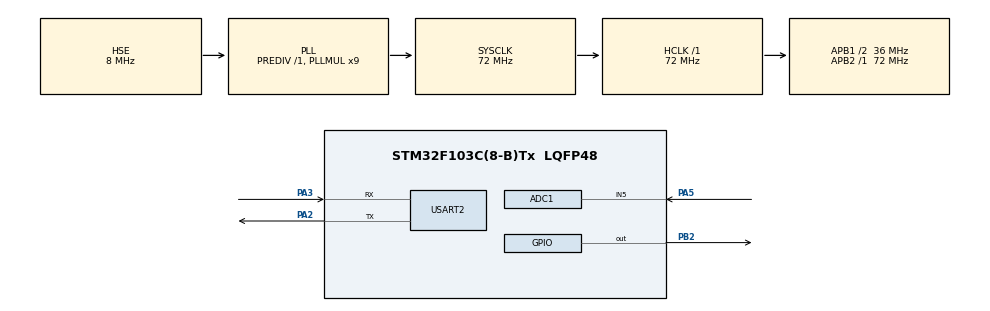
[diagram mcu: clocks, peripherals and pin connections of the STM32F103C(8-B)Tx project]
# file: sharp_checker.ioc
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ADC1.Channel-0\#ChannelRegularConversion=ADC_CHANNEL_5
ADC1.NbrOfConversionFlag=1
ADC1.Rank-0\#ChannelRegularConversion=1
ADC1.SamplingTime-0\#ChannelRegularConversion=ADC_SAMPLETIME_13CYCLES_5
ADC1.master=1
Mcu.Family=STM32F1
Mcu.Name=STM32F103C(8-B)Tx
Mcu.Package=LQFP48
NVIC.PriorityGroup=NVIC_PRIORITYGROUP_4
PA13.Mode=Serial_Wire
PA13.Signal=SYS_JTMS-SWDIO
PA14.Mode=Serial_Wire
PA14.Signal=SYS_JTCK-SWCLK
PA2.Mode=Asynchronous
PA2.Signal=USART2_TX
PA3.Mode=Asynchronous
PA3.Signal=USART2_RX
PA5.Signal=SharedAnalog_PA5
PB2.Signal=GPIO_Output
PD0-OSC_IN.Mode=HSE-External-Oscillator
PD0-OSC_IN.Signal=RCC_OSC_IN
PD1-OSC_OUT.Mode=HSE-External-Oscillator
PD1-OSC_OUT.Signal=RCC_OSC_OUT
ProjectManager.HeapSize=0x200
ProjectManager.StackSize=0x400
ProjectManager.TargetToolchain=STM32CubeIDE
RCC.AHBFreq_Value=72000000
RCC.APB1CLKDivider=RCC_HCLK_DIV2
RCC.APB1Freq_Value=36000000
RCC.APB1TimFreq_Value=72000000
RCC.APB2Freq_Value=72000000
RCC.APB2TimFreq_Value=72000000
RCC.EnbaleCSS=true
RCC.HCLKFreq_Value=72000000
RCC.PLLMUL=RCC_PLL_MUL9
RCC.PLLSourceVirtual=RCC_PLLSOURCE_HSE
RCC.SYSCLKFreq_VALUE=72000000
RCC.SYSCLKSource=RCC_SYSCLKSOURCE_PLLCLK
RCC.USBFreq_Value=72000000
SH.SharedAnalog_PA5.0=GPIO_Analog
SH.SharedAnalog_PA5.1=ADC1_IN5,IN5
USART2.VirtualMode=VM_ASYNC
board=custom

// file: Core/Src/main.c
/* USER CODE BEGIN Header */
/**
  ******************************************************************************
  * @file           : main.c
  * @brief          : Main program body
  ******************************************************************************
  * @attention
  *
  * Copyright (c) 2024 STMicroelectronics.
  * All rights reserved.
  *
  * This software is licensed under terms that can be found in the LICENSE file
  * in the root directory of this software component.
  * If no LICENSE file comes with this software, it is provided AS-IS.
  *
  ******************************************************************************
  */
/* USER CODE END Header */
#include "main.h"

#define MIN_DELAY 50  // Minimum delay in milliseconds
#define MAX_DELAY 1000 // Maximum delay in milliseconds

ADC_HandleTypeDef hadc1;
UART_HandleTypeDef huart2;

void SystemClock_Config(void);
static void MX_GPIO_Init(void);
static void MX_ADC1_Init(void);
static void MX_USART2_UART_Init(void);
uint32_t Read_Sharp_Sensor(void);

int main(void)
{

  /* MCU Configuration--------------------------------------------------------*/

  /* Reset of all peripherals, Initializes the Flash interface and the Systick. */
  HAL_Init();

  /* Configure the system clock */
  SystemClock_Config();

  /* Initialize all configured peripherals */
  MX_GPIO_Init();
  MX_ADC1_Init();
  MX_USART2_UART_Init();

  /* Infinite loop */
  /* USER CODE BEGIN WHILE */
  while (1)
  {
    uint32_t sensor_value = Read_Sharp_Sensor();
    uint32_t delay_time = MAX_DELAY - (sensor_value / 2); // Increase sensitivity

    // Ensure delay_time is within bounds
    if (delay_time < MIN_DELAY) {
      delay_time = MIN_DELAY;
    }

    HAL_GPIO_TogglePin(GPIOB, GPIO_PIN_2);
    HAL_Delay(delay_time);

    /* USER CODE END WHILE */

  }
}

/**
  * @ System Clock Configuration
  * @retval None
  */
void SystemClock_Config(void)
{
  RCC_OscInitTypeDef RCC_OscInitStruct = {0};
  RCC_ClkInitTypeDef RCC_ClkInitStruct = {0};
  RCC_PeriphCLKInitTypeDef PeriphClkInit = {0};

  /** Initializes the RCC Oscillators according to the specified parameters
  * in the RCC_OscInitTypeDef structure.
  */
  RCC_OscInitStruct.OscillatorType = RCC_OSCILLATORTYPE_HSE;
  RCC_OscInitStruct.HSEState = RCC_HSE_ON;
  RCC_OscInitStruct.HSEPredivValue = RCC_HSE_PREDIV_DIV1;
  RCC_OscInitStruct.HSIState = RCC_HSI_ON;
  RCC_OscInitStruct.PLL.PLLState = RCC_PLL_ON;
  RCC_OscInitStruct.PLL.PLLSource = RCC_PLLSOURCE_HSE;
  RCC_OscInitStruct.PLL.PLLMUL = RCC_PLL_MUL9;
  if (HAL_RCC_OscConfig(&RCC_OscInitStruct) != HAL_OK)
  {
    Error_Handler();
  }

  /** Initializes the CPU, AHB and APB buses clocks
  */
  RCC_ClkInitStruct.ClockType = RCC_CLOCKTYPE_HCLK|RCC_CLOCKTYPE_SYSCLK
                              |RCC_CLOCKTYPE_PCLK1|RCC_CLOCKTYPE_PCLK2;
  RCC_ClkInitStruct.SYSCLKSource = RCC_SYSCLKSOURCE_PLLCLK;
  RCC_ClkInitStruct.AHBCLKDivider = RCC_SYSCLK_DIV1;
  RCC_ClkInitStruct.APB1CLKDivider = RCC_HCLK_DIV2;
  RCC_ClkInitStruct.APB2CLKDivider = RCC_HCLK_DIV1;

  if (HAL_RCC_ClockConfig(&RCC_ClkInitStruct, FLASH_LATENCY_2) != HAL_OK)
  {
    Error_Handler();
  }
  PeriphClkInit.PeriphClockSelection = RCC_PERIPHCLK_ADC;
  PeriphClkInit.AdcClockSelection = RCC_ADCPCLK2_DIV2;
  if (HAL_RCCEx_PeriphCLKConfig(&PeriphClkInit) != HAL_OK)
  {
    Error_Handler();
  }

  /** Enables the Clock Security System
  */
  HAL_RCC_EnableCSS();
}

static void MX_ADC1_Init(void)
{
  ADC_ChannelConfTypeDef sConfig = {0};

  /** Common config
  */
  hadc1.Instance = ADC1;
  hadc1.Init.ScanConvMode = ADC_SCAN_DISABLE;
  hadc1.Init.ContinuousConvMode = DISABLE;
  hadc1.Init.DiscontinuousConvMode = DISABLE;
  hadc1.Init.ExternalTrigConv = ADC_SOFTWARE_START;
  hadc1.Init.DataAlign = ADC_DATAALIGN_RIGHT;
  hadc1.Init.NbrOfConversion = 1;
  if (HAL_ADC_Init(&hadc1) != HAL_OK)
  {
    Error_Handler();
  }

  /** Configure Regular Channel
  */
  sConfig.Channel = ADC_CHANNEL_5;
  sConfig.Rank = ADC_REGULAR_RANK_1;
  sConfig.SamplingTime = ADC_SAMPLETIME_13CYCLES_5;
  if (HAL_ADC_ConfigChannel(&hadc1, &sConfig) != HAL_OK)
  {
    Error_Handler();
  }
}

static void MX_USART2_UART_Init(void)
{
  huart2.Instance = USART2;
  huart2.Init.BaudRate = 115200;
  huart2.Init.WordLength = UART_WORDLENGTH_8B;
  huart2.Init.StopBits = UART_STOPBITS_1;
  huart2.Init.Parity = UART_PARITY_NONE;
  huart2.Init.Mode = UART_MODE_TX_RX;
  huart2.Init.HwFlowCtl = UART_HWCONTROL_NONE;
  huart2.Init.OverSampling = UART_OVERSAMPLING_16;
  if (HAL_UART_Init(&huart2) != HAL_OK)
  {
    Error_Handler();
  }
}

static void MX_GPIO_Init(void)
{
  GPIO_InitTypeDef GPIO_InitStruct = {0};

  /* GPIO Ports Clock Enable */
  __HAL_RCC_GPIOD_CLK_ENABLE();
  __HAL_RCC_GPIOA_CLK_ENABLE();
  __HAL_RCC_GPIOB_CLK_ENABLE();

  /*Configure GPIO pin Output Level */
  HAL_GPIO_WritePin(GPIOB, GPIO_PIN_2, GPIO_PIN_RESET);

  /*Configure GPIO pin : PB2 */
  GPIO_InitStruct.Pin = GPIO_PIN_2;
  GPIO_InitStruct.Mode = GPIO_MODE_OUTPUT_PP;
  GPIO_InitStruct.Pull = GPIO_NOPULL;
  GPIO_InitStruct.Speed = GPIO_SPEED_FREQ_LOW;
  HAL_GPIO_Init(GPIOB, &GPIO_InitStruct);
}

/**
  * @brief  Reads the value from the Sharp IR sensor
  * @retval uint32_t: ADC value
  */
uint32_t Read_Sharp_Sensor(void)
{
  HAL_ADC_Start(&hadc1);
  HAL_ADC_PollForConversion(&hadc1, HAL_MAX_DELAY);
  uint32_t value = HAL_ADC_GetValue(&hadc1);
  HAL_ADC_Stop(&hadc1);
  return value;
}

void Error_Handler(void)
{
  __disable_irq();
  while (1)
  {
  }
}
